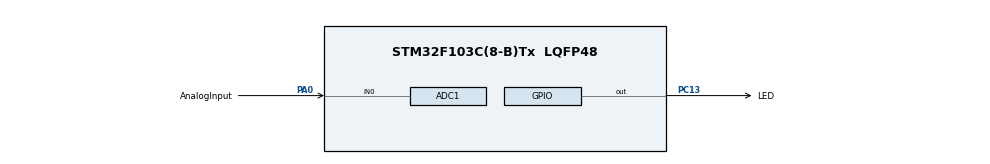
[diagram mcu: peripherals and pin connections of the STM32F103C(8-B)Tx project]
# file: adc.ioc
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ADC1.Channel-0\#ChannelRegularConversion=ADC_CHANNEL_0
ADC1.NbrOfConversionFlag=1
ADC1.Rank-0\#ChannelRegularConversion=1
ADC1.SamplingTime-0\#ChannelRegularConversion=ADC_SAMPLETIME_1CYCLE_5
ADC1.master=1
Mcu.Family=STM32F1
Mcu.Name=STM32F103C(8-B)Tx
Mcu.Package=LQFP48
NVIC.PriorityGroup=NVIC_PRIORITYGROUP_4
PA0-WKUP.GPIO_Label=AnalogInput
PA0-WKUP.Signal=ADCx_IN0
PC13-TAMPER-RTC.GPIO_Label=LED
PC13-TAMPER-RTC.PinState=GPIO_PIN_SET
PC13-TAMPER-RTC.Signal=GPIO_Output
ProjectManager.HeapSize=0x200
ProjectManager.StackSize=0x400
ProjectManager.TargetToolchain=STM32CubeIDE
RCC.APB1Freq_Value=8000000
RCC.APB2Freq_Value=8000000
SH.ADCx_IN0.0=ADC1_IN0,IN0
VP_SYS_VS_ND.Mode=No_Debug
board=custom

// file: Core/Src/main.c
/* USER CODE BEGIN Header */
/**
  ******************************************************************************
  * @file           : main.c
  * @brief          : Main program body
  ******************************************************************************
  * @attention
  *
  * Copyright (c) 2024 STMicroelectronics.
  * All rights reserved.
  *
  * This software is licensed under terms that can be found in the LICENSE file
  * in the root directory of this software component.
  * If no LICENSE file comes with this software, it is provided AS-IS.
  *
  ******************************************************************************
  */
/* USER CODE END Header */
#include "main.h"

ADC_HandleTypeDef hadc1;

void SystemClock_Config(void);
static void MX_GPIO_Init(void);
static void MX_ADC1_Init(void);

int main(void)
{

  /* MCU Configuration--------------------------------------------------------*/

  /* Reset of all peripherals, Initializes the Flash interface and the Systick. */
  HAL_Init();

  /* Configure the system clock */
  SystemClock_Config();

  /* Initialize all configured peripherals */
  MX_GPIO_Init();
  MX_ADC1_Init();

  /* Infinite loop */
  /* USER CODE BEGIN WHILE */
  uint16_t result = 0;
  while (1)
  {
	  // Use alalog input to change blink rate (via result).

	  HAL_ADC_Start(&hadc1);
	  HAL_ADC_PollForConversion(&hadc1, 1);
	  result = HAL_ADC_GetValue(&hadc1);

	  HAL_GPIO_TogglePin(LED_GPIO_Port, LED_Pin);
	  HAL_Delay(result * 4);
    /* USER CODE END WHILE */

  }
}

void SystemClock_Config(void)
{
  RCC_OscInitTypeDef RCC_OscInitStruct = {0};
  RCC_ClkInitTypeDef RCC_ClkInitStruct = {0};
  RCC_PeriphCLKInitTypeDef PeriphClkInit = {0};

  /** Initializes the RCC Oscillators according to the specified parameters
  * in the RCC_OscInitTypeDef structure.
  */
  RCC_OscInitStruct.OscillatorType = RCC_OSCILLATORTYPE_HSI;
  RCC_OscInitStruct.HSIState = RCC_HSI_ON;
  RCC_OscInitStruct.HSICalibrationValue = RCC_HSICALIBRATION_DEFAULT;
  RCC_OscInitStruct.PLL.PLLState = RCC_PLL_NONE;
  if (HAL_RCC_OscConfig(&RCC_OscInitStruct) != HAL_OK)
  {
    Error_Handler();
  }

  /** Initializes the CPU, AHB and APB buses clocks
  */
  RCC_ClkInitStruct.ClockType = RCC_CLOCKTYPE_HCLK|RCC_CLOCKTYPE_SYSCLK
                              |RCC_CLOCKTYPE_PCLK1|RCC_CLOCKTYPE_PCLK2;
  RCC_ClkInitStruct.SYSCLKSource = RCC_SYSCLKSOURCE_HSI;
  RCC_ClkInitStruct.AHBCLKDivider = RCC_SYSCLK_DIV1;
  RCC_ClkInitStruct.APB1CLKDivider = RCC_HCLK_DIV1;
  RCC_ClkInitStruct.APB2CLKDivider = RCC_HCLK_DIV1;

  if (HAL_RCC_ClockConfig(&RCC_ClkInitStruct, FLASH_LATENCY_0) != HAL_OK)
  {
    Error_Handler();
  }
  PeriphClkInit.PeriphClockSelection = RCC_PERIPHCLK_ADC;
  PeriphClkInit.AdcClockSelection = RCC_ADCPCLK2_DIV2;
  if (HAL_RCCEx_PeriphCLKConfig(&PeriphClkInit) != HAL_OK)
  {
    Error_Handler();
  }
}

static void MX_ADC1_Init(void)
{

  ADC_ChannelConfTypeDef sConfig = {0};

  /** Common config
  */
  hadc1.Instance = ADC1;
  hadc1.Init.ScanConvMode = ADC_SCAN_DISABLE;
  hadc1.Init.ContinuousConvMode = DISABLE;
  hadc1.Init.DiscontinuousConvMode = DISABLE;
  hadc1.Init.ExternalTrigConv = ADC_SOFTWARE_START;
  hadc1.Init.DataAlign = ADC_DATAALIGN_RIGHT;
  hadc1.Init.NbrOfConversion = 1;
  if (HAL_ADC_Init(&hadc1) != HAL_OK)
  {
    Error_Handler();
  }

  /** Configure Regular Channel
  */
  sConfig.Channel = ADC_CHANNEL_0;
  sConfig.Rank = ADC_REGULAR_RANK_1;
  sConfig.SamplingTime = ADC_SAMPLETIME_1CYCLE_5;
  if (HAL_ADC_ConfigChannel(&hadc1, &sConfig) != HAL_OK)
  {
    Error_Handler();
  }

}

static void MX_GPIO_Init(void)
{
  GPIO_InitTypeDef GPIO_InitStruct = {0};

  /* GPIO Ports Clock Enable */
  __HAL_RCC_GPIOC_CLK_ENABLE();
  __HAL_RCC_GPIOA_CLK_ENABLE();

  /*Configure GPIO pin Output Level */
  HAL_GPIO_WritePin(LED_GPIO_Port, LED_Pin, GPIO_PIN_SET);

  /*Configure GPIO pin : LED_Pin */
  GPIO_InitStruct.Pin = LED_Pin;
  GPIO_InitStruct.Mode = GPIO_MODE_OUTPUT_PP;
  GPIO_InitStruct.Pull = GPIO_NOPULL;
  GPIO_InitStruct.Speed = GPIO_SPEED_FREQ_LOW;
  HAL_GPIO_Init(LED_GPIO_Port, &GPIO_InitStruct);

}

void Error_Handler(void)
{
  __disable_irq();
  while (1)
  {
  }
}
